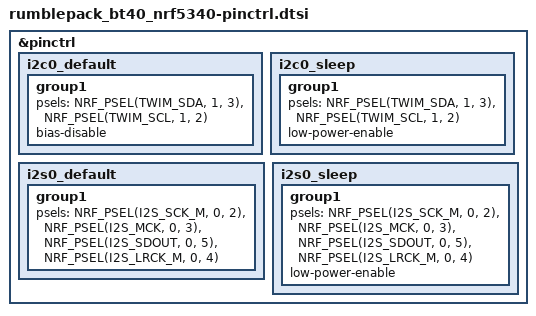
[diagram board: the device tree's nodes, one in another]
&pinctrl{
    i2c0_default: i2c0_default {
		group1 {
			psels = <NRF_PSEL(TWIM_SDA, 1, 3)>,
				    <NRF_PSEL(TWIM_SCL, 1, 2)>;
            bias-disable;
		};
	};

	i2c0_sleep: i2c0_sleep {
		group1 {
			psels = <NRF_PSEL(TWIM_SDA, 1, 3)>,
				    <NRF_PSEL(TWIM_SCL, 1, 2)>;
			low-power-enable;
		};
	};

    i2s0_default: i2s0_default {
        group1 {
            psels = <NRF_PSEL(I2S_SCK_M, 0, 2)>,
                    <NRF_PSEL(I2S_MCK, 0, 3)>,
                    <NRF_PSEL(I2S_SDOUT, 0, 5)>,
                    <NRF_PSEL(I2S_LRCK_M, 0, 4)>;
        };
    };
    i2s0_sleep: i2s0_sleep {
        group1 {
            psels = <NRF_PSEL(I2S_SCK_M, 0, 2)>,
                    <NRF_PSEL(I2S_MCK, 0, 3)>,
                    <NRF_PSEL(I2S_SDOUT, 0, 5)>,
                    <NRF_PSEL(I2S_LRCK_M, 0, 4)>;
            low-power-enable;
        };
    };
};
